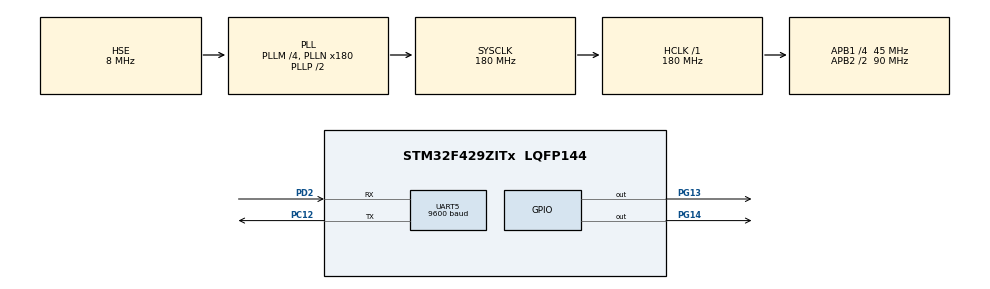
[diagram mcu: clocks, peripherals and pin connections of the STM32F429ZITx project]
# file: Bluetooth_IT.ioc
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Mcu.Family=STM32F4
Mcu.Name=STM32F429ZITx
Mcu.Package=LQFP144
NVIC.PriorityGroup=NVIC_PRIORITYGROUP_4
NVIC.UART5_IRQn=true\:0\:0\:false\:false\:true\:true\:true
PC12.Mode=Asynchronous
PC12.Signal=UART5_TX
PD2.Mode=Asynchronous
PD2.Signal=UART5_RX
PG13.Signal=GPIO_Output
PG14.Signal=GPIO_Output
PH0/OSC_IN.Mode=HSE-External-Oscillator
PH0/OSC_IN.Signal=RCC_OSC_IN
PH1/OSC_OUT.Mode=HSE-External-Oscillator
PH1/OSC_OUT.Signal=RCC_OSC_OUT
ProjectManager.HeapSize=0x200
ProjectManager.StackSize=0x400
ProjectManager.TargetToolchain=MDK-ARM V5.27
RCC.48MHZClocksFreq_Value=90000000
RCC.AHBFreq_Value=180000000
RCC.APB1CLKDivider=RCC_HCLK_DIV4
RCC.APB1Freq_Value=45000000
RCC.APB1TimFreq_Value=90000000
RCC.APB2CLKDivider=RCC_HCLK_DIV2
RCC.APB2Freq_Value=90000000
RCC.APB2TimFreq_Value=180000000
RCC.CortexFreq_Value=180000000
RCC.HCLKFreq_Value=180000000
RCC.HSE_VALUE=8000000
RCC.HSI_VALUE=16000000
RCC.LSE_VALUE=32768
RCC.PLLM=4
RCC.PLLN=180
RCC.PLLSourceVirtual=RCC_PLLSOURCE_HSE
RCC.SYSCLKFreq_VALUE=180000000
RCC.SYSCLKSource=RCC_SYSCLKSOURCE_PLLCLK
RCC.VCOOutputFreq_Value=360000000
UART5.BaudRate=9600
UART5.VirtualMode=Asynchronous
board=custom

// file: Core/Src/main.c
/* USER CODE BEGIN Header */
/**
  ******************************************************************************
  * @file           : main.c
  * @brief          : Main program body
  ******************************************************************************
  * @attention
  *
  * <h2><center>&copy; Copyright (c) 2020 STMicroelectronics.
  * All rights reserved.</center></h2>
  *
  * This software component is licensed by ST under BSD 3-Clause license,
  * the "License"; You may not use this file except in compliance with the
  * License. You may obtain a copy of the License at:
  *                        opensource.org/licenses/BSD-3-Clause
  *
  ******************************************************************************
  */
/* USER CODE END Header */
#include "main.h"

/* USER CODE BEGIN PTD */

char tx_buffer[8], rx_buffer[8];

/* USER CODE END PTD */

UART_HandleTypeDef huart5;

void SystemClock_Config(void);
static void MX_GPIO_Init(void);
static void MX_UART5_Init(void);

/* USER CODE BEGIN 0 */

void HAL_UART_TxCpltCallback(UART_HandleTypeDef *huart){

		HAL_GPIO_WritePin(GPIOG, GPIO_PIN_13, GPIO_PIN_SET);

}

void HAL_UART_RxCpltCallback(UART_HandleTypeDef *huart){

		HAL_GPIO_TogglePin(GPIOG, GPIO_PIN_13);

	  HAL_UART_Transmit_IT(&huart5, (uint8_t*)tx_buffer, sprintf(tx_buffer, "Led1 Turned on\n"));

}

/* USER CODE END 0 */

int main(void)
{

  /* MCU Configuration--------------------------------------------------------*/

  /* Reset of all peripherals, Initializes the Flash interface and the Systick. */
  HAL_Init();

  /* Configure the system clock */
  SystemClock_Config();

  /* Initialize all configured peripherals */
  MX_GPIO_Init();
  MX_UART5_Init();
  /* USER CODE BEGIN 2 */

	HAL_Delay(1000);

		HAL_UART_Transmit_IT(&huart5, (uint8_t*)tx_buffer, sprintf(tx_buffer, "Hello world\n"));

  /* USER CODE END 2 */

  /* Infinite loop */
  while (1)
  {

    /* USER CODE BEGIN 3 */

		HAL_UART_Receive_IT(&huart5, (uint8_t*)rx_buffer, sizeof rx_buffer);

		if(rx_buffer[3] == '1' && rx_buffer[6] == 'n'){

				HAL_GPIO_WritePin(GPIOG, GPIO_PIN_14, GPIO_PIN_SET);

		}
		else if(rx_buffer[3] == '1' && rx_buffer[6] == 'f'){

				HAL_GPIO_WritePin(GPIOG, GPIO_PIN_14, GPIO_PIN_RESET);

		}

  }
  /* USER CODE END 3 */
}

void SystemClock_Config(void)
{
  RCC_OscInitTypeDef RCC_OscInitStruct = {0};
  RCC_ClkInitTypeDef RCC_ClkInitStruct = {0};

  /** Configure the main internal regulator output voltage
  */
  __HAL_RCC_PWR_CLK_ENABLE();
  __HAL_PWR_VOLTAGESCALING_CONFIG(PWR_REGULATOR_VOLTAGE_SCALE1);
  /** Initializes the RCC Oscillators according to the specified parameters
  * in the RCC_OscInitTypeDef structure.
  */
  RCC_OscInitStruct.OscillatorType = RCC_OSCILLATORTYPE_HSE;
  RCC_OscInitStruct.HSEState = RCC_HSE_ON;
  RCC_OscInitStruct.PLL.PLLState = RCC_PLL_ON;
  RCC_OscInitStruct.PLL.PLLSource = RCC_PLLSOURCE_HSE;
  RCC_OscInitStruct.PLL.PLLM = 4;
  RCC_OscInitStruct.PLL.PLLN = 180;
  RCC_OscInitStruct.PLL.PLLP = RCC_PLLP_DIV2;
  RCC_OscInitStruct.PLL.PLLQ = 4;
  if (HAL_RCC_OscConfig(&RCC_OscInitStruct) != HAL_OK)
  {
    Error_Handler();
  }
  /** Activate the Over-Drive mode
  */
  if (HAL_PWREx_EnableOverDrive() != HAL_OK)
  {
    Error_Handler();
  }
  /** Initializes the CPU, AHB and APB buses clocks
  */
  RCC_ClkInitStruct.ClockType = RCC_CLOCKTYPE_HCLK|RCC_CLOCKTYPE_SYSCLK
                              |RCC_CLOCKTYPE_PCLK1|RCC_CLOCKTYPE_PCLK2;
  RCC_ClkInitStruct.SYSCLKSource = RCC_SYSCLKSOURCE_PLLCLK;
  RCC_ClkInitStruct.AHBCLKDivider = RCC_SYSCLK_DIV1;
  RCC_ClkInitStruct.APB1CLKDivider = RCC_HCLK_DIV4;
  RCC_ClkInitStruct.APB2CLKDivider = RCC_HCLK_DIV2;

  if (HAL_RCC_ClockConfig(&RCC_ClkInitStruct, FLASH_LATENCY_5) != HAL_OK)
  {
    Error_Handler();
  }
}

static void MX_UART5_Init(void)
{

  huart5.Instance = UART5;
  huart5.Init.BaudRate = 9600;
  huart5.Init.WordLength = UART_WORDLENGTH_8B;
  huart5.Init.StopBits = UART_STOPBITS_1;
  huart5.Init.Parity = UART_PARITY_NONE;
  huart5.Init.Mode = UART_MODE_TX_RX;
  huart5.Init.HwFlowCtl = UART_HWCONTROL_NONE;
  huart5.Init.OverSampling = UART_OVERSAMPLING_16;
  if (HAL_UART_Init(&huart5) != HAL_OK)
  {
    Error_Handler();
  }

}

static void MX_GPIO_Init(void)
{
  GPIO_InitTypeDef GPIO_InitStruct = {0};

  /* GPIO Ports Clock Enable */
  __HAL_RCC_GPIOH_CLK_ENABLE();
  __HAL_RCC_GPIOC_CLK_ENABLE();
  __HAL_RCC_GPIOD_CLK_ENABLE();
  __HAL_RCC_GPIOG_CLK_ENABLE();

  /*Configure GPIO pin Output Level */
  HAL_GPIO_WritePin(GPIOG, GPIO_PIN_13|GPIO_PIN_14, GPIO_PIN_RESET);

  /*Configure GPIO pins : PG13 PG14 */
  GPIO_InitStruct.Pin = GPIO_PIN_13|GPIO_PIN_14;
  GPIO_InitStruct.Mode = GPIO_MODE_OUTPUT_PP;
  GPIO_InitStruct.Pull = GPIO_NOPULL;
  GPIO_InitStruct.Speed = GPIO_SPEED_FREQ_LOW;
  HAL_GPIO_Init(GPIOG, &GPIO_InitStruct);

}

void Error_Handler(void)
{
}

/************************ (C) COPYRIGHT STMicroelectronics *****END OF FILE****/
